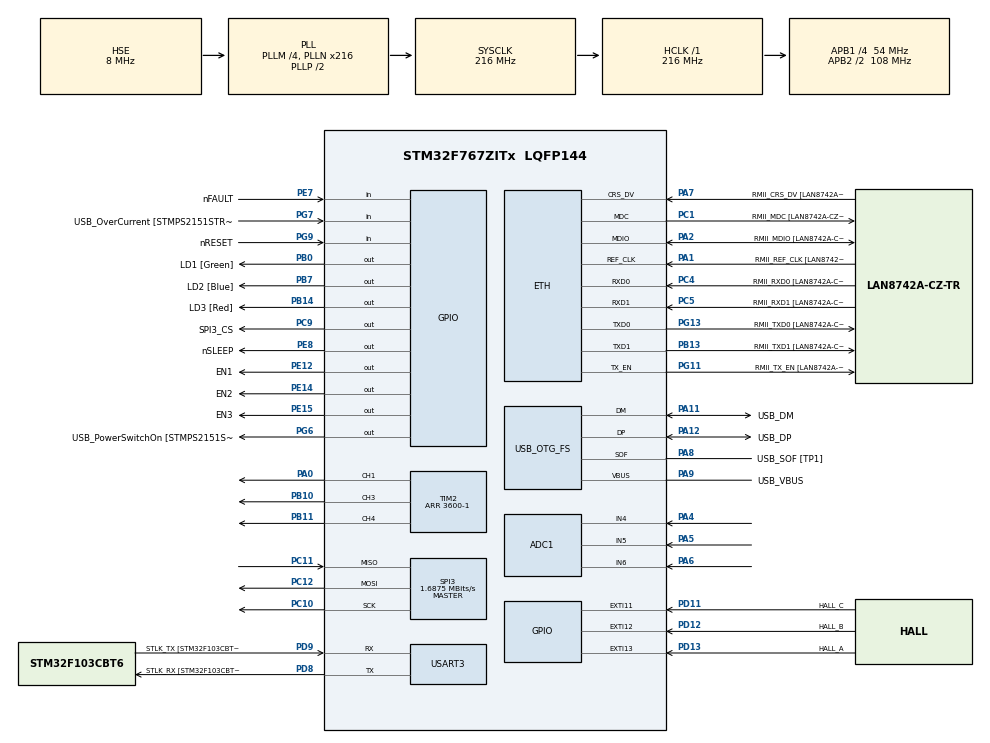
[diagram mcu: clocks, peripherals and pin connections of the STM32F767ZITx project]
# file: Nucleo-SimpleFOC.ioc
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ADC1.Channel-0\#ChannelRegularConversion=ADC_CHANNEL_5
ADC1.Channel-1\#ChannelRegularConversion=ADC_CHANNEL_6
ADC1.Channel-3\#ChannelRegularConversion=ADC_CHANNEL_4
ADC1.ContinuousConvMode=ENABLE
ADC1.DMAContinuousRequests=ENABLE
ADC1.DiscontinuousConvMode=DISABLE
ADC1.EOCSelection=ADC_EOC_SEQ_CONV
ADC1.NbrOfConversion=3
ADC1.NbrOfConversionFlag=1
ADC1.Rank-0\#ChannelRegularConversion=1
ADC1.Rank-1\#ChannelRegularConversion=2
ADC1.Rank-3\#ChannelRegularConversion=3
ADC1.SamplingTime-0\#ChannelRegularConversion=ADC_SAMPLETIME_28CYCLES
ADC1.SamplingTime-1\#ChannelRegularConversion=ADC_SAMPLETIME_28CYCLES
ADC1.SamplingTime-3\#ChannelRegularConversion=ADC_SAMPLETIME_28CYCLES
ADC1.ScanConvMode=ADC_SCAN_ENABLE
ADC1.master=1
Dma.ADC1.0.Direction=DMA_PERIPH_TO_MEMORY
Dma.ADC1.0.FIFOMode=DMA_FIFOMODE_DISABLE
Dma.ADC1.0.Instance=DMA2_Stream0
Dma.ADC1.0.MemDataAlignment=DMA_MDATAALIGN_HALFWORD
Dma.ADC1.0.MemInc=DMA_MINC_ENABLE
Dma.ADC1.0.Mode=DMA_CIRCULAR
Dma.ADC1.0.PeriphDataAlignment=DMA_PDATAALIGN_HALFWORD
Dma.ADC1.0.PeriphInc=DMA_PINC_DISABLE
Dma.ADC1.0.Priority=DMA_PRIORITY_LOW
Dma.Request0=ADC1
ETH.MediaInterface=HAL_ETH_RMII_MODE
ETH.PHY_Name=LAN8742A_PHY_ADDRESS
ETH.PHY_Value=0
ETH.PhyAddress=0
Mcu.Family=STM32F7
Mcu.Name=STM32F767ZITx
Mcu.Package=LQFP144
NVIC.DMA2_Stream0_IRQn=true\:0\:0\:false\:false\:true\:false\:true\:true
NVIC.EXTI15_10_IRQn=true\:0\:0\:false\:false\:true\:true\:true\:true
NVIC.PriorityGroup=NVIC_PRIORITYGROUP_4
NVIC.TIM1_UP_TIM10_IRQn=true\:0\:0\:false\:false\:true\:true\:true\:true
PA0/WKUP.Signal=S_TIM2_CH1_ETR
PA1.GPIO_Label=RMII_REF_CLK [LAN8742A-CZ-TR_REFCLK0]
PA1.Mode=RMII
PA1.Signal=ETH_REF_CLK
PA10.GPIO_Label=USB_ID
PA10.Signal=USB_OTG_FS_ID
PA11.GPIO_Label=USB_DM
PA11.Mode=Device_Only
PA11.Signal=USB_OTG_FS_DM
PA12.GPIO_Label=USB_DP
PA12.Mode=Device_Only
PA12.Signal=USB_OTG_FS_DP
PA13.GPIO_Label=TMS
PA13.Mode=Serial_Wire
PA13.Signal=SYS_JTMS-SWDIO
PA14.GPIO_Label=TCK
PA14.Mode=Serial_Wire
PA14.Signal=SYS_JTCK-SWCLK
PA2.GPIO_Label=RMII_MDIO [LAN8742A-CZ-TR_MDIO]
PA2.Mode=RMII
PA2.Signal=ETH_MDIO
PA4.Signal=ADCx_IN4
PA5.Signal=ADCx_IN5
PA6.Signal=ADCx_IN6
PA7.GPIO_Label=RMII_CRS_DV [LAN8742A-CZ-TR_CRS_DV]
PA7.Mode=RMII
PA7.Signal=ETH_CRS_DV
PA8.GPIO_Label=USB_SOF [TP1]
PA8.Mode=Activate_SOF_FS
PA8.Signal=USB_OTG_FS_SOF
PA9.GPIO_Label=USB_VBUS
PA9.Mode=Activate_VBUS
PA9.Signal=USB_OTG_FS_VBUS
PB0.GPIO_Label=LD1 [Green]
PB0.Signal=GPIO_Output
PB10.Signal=S_TIM2_CH3
PB11.Signal=S_TIM2_CH4
PB13.GPIO_Label=RMII_TXD1 [LAN8742A-CZ-TR_TXD1]
PB13.Mode=RMII
PB13.Signal=ETH_TXD1
PB14.GPIO_Label=LD3 [Red]
PB14.Signal=GPIO_Output
PB3.GPIO_Label=SWO
PB3.Signal=SYS_JTDO-SWO
PB7.GPIO_Label=LD2 [Blue]
PB7.Signal=GPIO_Output
PC1.GPIO_Label=RMII_MDC [LAN8742A-CZ-TR_MDC]
PC1.Mode=RMII
PC1.Signal=ETH_MDC
PC10.Mode=Full_Duplex_Master
PC10.Signal=SPI3_SCK
PC11.Mode=Full_Duplex_Master
PC11.Signal=SPI3_MISO
PC12.Mode=Full_Duplex_Master
PC12.Signal=SPI3_MOSI
PC14/OSC32_IN.Mode=LSE-External-Oscillator
PC14/OSC32_IN.Signal=RCC_OSC32_IN
PC15/OSC32_OUT.Mode=LSE-External-Oscillator
PC15/OSC32_OUT.Signal=RCC_OSC32_OUT
PC4.GPIO_Label=RMII_RXD0 [LAN8742A-CZ-TR_RXD0]
PC4.Mode=RMII
PC4.Signal=ETH_RXD0
PC5.GPIO_Label=RMII_RXD1 [LAN8742A-CZ-TR_RXD1]
PC5.Mode=RMII
PC5.Signal=ETH_RXD1
PC9.GPIO_Label=SPI3_CS
PC9.Signal=GPIO_Output
PD11.GPIO_Label=HALL_C
PD11.GPIO_ModeDefaultEXTI=GPIO_MODE_IT_RISING_FALLING
PD11.GPIO_PuPd=GPIO_PULLUP
PD11.Signal=GPXTI11
PD12.GPIO_Label=HALL_B
PD12.GPIO_ModeDefaultEXTI=GPIO_MODE_IT_RISING_FALLING
PD12.GPIO_PuPd=GPIO_PULLUP
PD12.Signal=GPXTI12
PD13.GPIO_Label=HALL_A
PD13.GPIO_ModeDefaultEXTI=GPIO_MODE_IT_RISING_FALLING
PD13.GPIO_PuPd=GPIO_PULLUP
PD13.Signal=GPXTI13
PD8.GPIO_Label=STLK_RX [STM32F103CBT6_PA3]
PD8.Mode=Asynchronous
PD8.Signal=USART3_TX
PD9.GPIO_Label=STLK_TX [STM32F103CBT6_PA2]
PD9.Mode=Asynchronous
PD9.Signal=USART3_RX
PE12.GPIO_Label=EN1
PE12.Signal=GPIO_Output
PE14.GPIO_Label=EN2
PE14.Signal=GPIO_Output
PE15.GPIO_Label=EN3
PE15.Signal=GPIO_Output
PE7.GPIO_Label=nFAULT
PE7.Signal=GPIO_Input
PE8.GPIO_Label=nSLEEP
PE8.Signal=GPIO_Output
PG11.GPIO_Label=RMII_TX_EN [LAN8742A-CZ-TR_TXEN]
PG11.Mode=RMII
PG11.Signal=ETH_TX_EN
PG13.GPIO_Label=RMII_TXD0 [LAN8742A-CZ-TR_TXD0]
PG13.Mode=RMII
PG13.Signal=ETH_TXD0
PG6.GPIO_Label=USB_PowerSwitchOn [STMPS2151STR_EN]
PG6.Signal=GPIO_Output
PG7.GPIO_Label=USB_OverCurrent [STMPS2151STR_FAULT]
PG7.Signal=GPIO_Input
PG9.GPIO_Label=nRESET
PG9.Signal=GPIO_Input
PH0/OSC_IN.GPIO_Label=MCO [STM32F103CBT6_PA8]
PH0/OSC_IN.Mode=HSE-External-Clock-Source
PH0/OSC_IN.Signal=RCC_OSC_IN
PH1/OSC_OUT.Mode=HSE-External-Clock-Source
PH1/OSC_OUT.Signal=RCC_OSC_OUT
ProjectManager.HeapSize=0x200
ProjectManager.StackSize=0x400
ProjectManager.TargetToolchain=Makefile
RCC.48MHZClocksFreq_Value=24000000
RCC.AHBFreq_Value=216000000
RCC.APB1CLKDivider=RCC_HCLK_DIV4
RCC.APB1Freq_Value=54000000
RCC.APB1TimFreq_Value=108000000
RCC.APB2CLKDivider=RCC_HCLK_DIV2
RCC.APB2Freq_Value=108000000
RCC.APB2TimFreq_Value=216000000
RCC.CortexFreq_Value=216000000
RCC.HCLKFreq_Value=216000000
RCC.HSE_VALUE=8000000
RCC.HSI_VALUE=16000000
RCC.PLLM=4
RCC.PLLMUL=RCC_PLL_MUL9
RCC.PLLN=216
RCC.PLLQ=9
RCC.PRESCALERUSB=RCC_USBCLKSOURCE_PLL_DIV1_5
RCC.SYSCLKFreq_VALUE=216000000
RCC.SYSCLKSource=RCC_SYSCLKSOURCE_PLLCLK
RCC.SYSCLKSourceVirtual=RCC_SYSCLKSOURCE_PLLCLK
RCC.USBFreq_Value=48000000
RCC.VCOOutputFreq_Value=432000000
SH.ADCx_IN4.0=ADC1_IN4,IN4
SH.ADCx_IN5.0=ADC1_IN5,IN5
SH.ADCx_IN6.0=ADC1_IN6,IN6
SH.S_TIM2_CH1_ETR.0=TIM2_CH1,PWM Generation1 CH1
SH.S_TIM2_CH3.0=TIM2_CH3,PWM Generation3 CH3
SH.S_TIM2_CH4.0=TIM2_CH4,PWM Generation4 CH4
SPI3.BaudRatePrescaler=SPI_BAUDRATEPRESCALER_32
SPI3.CLKPhase=SPI_PHASE_2EDGE
SPI3.CLKPolarity=SPI_POLARITY_LOW
SPI3.CalculateBaudRate=1.6875 MBits/s
SPI3.DataSize=SPI_DATASIZE_8BIT
SPI3.Direction=SPI_DIRECTION_2LINES
SPI3.Mode=SPI_MODE_MASTER
SPI3.VirtualType=VM_MASTER
TIM1.Period=1000-1
TIM1.Prescaler=216-1
TIM2.Channel-PWM\ Generation1\ CH1=TIM_CHANNEL_1
TIM2.Channel-PWM\ Generation3\ CH3=TIM_CHANNEL_3
TIM2.Channel-PWM\ Generation4\ CH4=TIM_CHANNEL_4
TIM2.Period=3600-1
USART3.VirtualMode-Asynchronous=VM_ASYNC
USB_OTG_FS.VirtualMode=Device_Only
VP_TIM1_VS_ClockSourceINT.Mode=Internal
board=NUCLEO-F767ZI

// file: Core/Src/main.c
/* USER CODE BEGIN Header */
/**
 ******************************************************************************
 * @file           : main.c
 * @brief          : Main program body
 ******************************************************************************
 * @attention
 *
 * Copyright (c) 2024 STMicroelectronics.
 * All rights reserved.
 *
 * This software is licensed under terms that can be found in the LICENSE file
 * in the root directory of this software component.
 * If no LICENSE file comes with this software, it is provided AS-IS.
 *
 ******************************************************************************
 */
/* USER CODE END Header */
#include "main.h"
#include "adc.h"
#include "dma.h"
#include "eth.h"
#include "spi.h"
#include "tim.h"
#include "usart.h"
#include "usb_otg.h"
#include "gpio.h"

/* USER CODE BEGIN Includes */
#include "main_exec.h"
/* USER CODE END Includes */

void SystemClock_Config(void);

/* USER CODE BEGIN 0 */
int cnt1kHz = 0;
int cnt30kHz = 0;
void HAL_TIM_PeriodElapsedCallback(TIM_HandleTypeDef *htim)
{
  if (htim->Instance == TIM1)
  {
    cnt1kHz = (cnt1kHz + 1) % 1000;
    timerCallback();

    if (cnt1kHz == 0)
      Toggle_GPIO(LED_LD1);
  }
}
/* USER CODE END 0 */

int main(void)
{

  /* MCU Configuration--------------------------------------------------------*/

  /* Reset of all peripherals, Initializes the Flash interface and the Systick. */
  HAL_Init();

  /* Configure the system clock */
  SystemClock_Config();

  /* Initialize all configured peripherals */
  MX_GPIO_Init();
  MX_DMA_Init();
  MX_USART3_UART_Init();
  MX_USB_OTG_FS_PCD_Init();
  MX_TIM1_Init();
  MX_SPI3_Init();
  MX_ETH_Init();
  MX_ADC1_Init();
  MX_TIM2_Init();
  /* USER CODE BEGIN 2 */
  setup();
  HAL_TIM_Base_Start_IT(&htim1);
  /* USER CODE END 2 */

  /* Infinite loop */
  while (1)
  {

  }
}

void SystemClock_Config(void)
{
  RCC_OscInitTypeDef RCC_OscInitStruct = {0};
  RCC_ClkInitTypeDef RCC_ClkInitStruct = {0};

  /** Configure LSE Drive Capability
  */
  HAL_PWR_EnableBkUpAccess();

  /** Configure the main internal regulator output voltage
  */
  __HAL_RCC_PWR_CLK_ENABLE();
  __HAL_PWR_VOLTAGESCALING_CONFIG(PWR_REGULATOR_VOLTAGE_SCALE1);

  /** Initializes the RCC Oscillators according to the specified parameters
  * in the RCC_OscInitTypeDef structure.
  */
  RCC_OscInitStruct.OscillatorType = RCC_OSCILLATORTYPE_HSE;
  RCC_OscInitStruct.HSEState = RCC_HSE_BYPASS;
  RCC_OscInitStruct.PLL.PLLState = RCC_PLL_ON;
  RCC_OscInitStruct.PLL.PLLSource = RCC_PLLSOURCE_HSE;
  RCC_OscInitStruct.PLL.PLLM = 4;
  RCC_OscInitStruct.PLL.PLLN = 216;
  RCC_OscInitStruct.PLL.PLLP = RCC_PLLP_DIV2;
  RCC_OscInitStruct.PLL.PLLQ = 9;
  RCC_OscInitStruct.PLL.PLLR = 2;
  if (HAL_RCC_OscConfig(&RCC_OscInitStruct) != HAL_OK)
  {
    Error_Handler();
  }

  /** Activate the Over-Drive mode
  */
  if (HAL_PWREx_EnableOverDrive() != HAL_OK)
  {
    Error_Handler();
  }

  /** Initializes the CPU, AHB and APB buses clocks
  */
  RCC_ClkInitStruct.ClockType = RCC_CLOCKTYPE_HCLK|RCC_CLOCKTYPE_SYSCLK
                              |RCC_CLOCKTYPE_PCLK1|RCC_CLOCKTYPE_PCLK2;
  RCC_ClkInitStruct.SYSCLKSource = RCC_SYSCLKSOURCE_PLLCLK;
  RCC_ClkInitStruct.AHBCLKDivider = RCC_SYSCLK_DIV1;
  RCC_ClkInitStruct.APB1CLKDivider = RCC_HCLK_DIV4;
  RCC_ClkInitStruct.APB2CLKDivider = RCC_HCLK_DIV2;

  if (HAL_RCC_ClockConfig(&RCC_ClkInitStruct, FLASH_LATENCY_7) != HAL_OK)
  {
    Error_Handler();
  }
}

void Error_Handler(void)
{
  __disable_irq();
  while (1)
  {
  }
}
